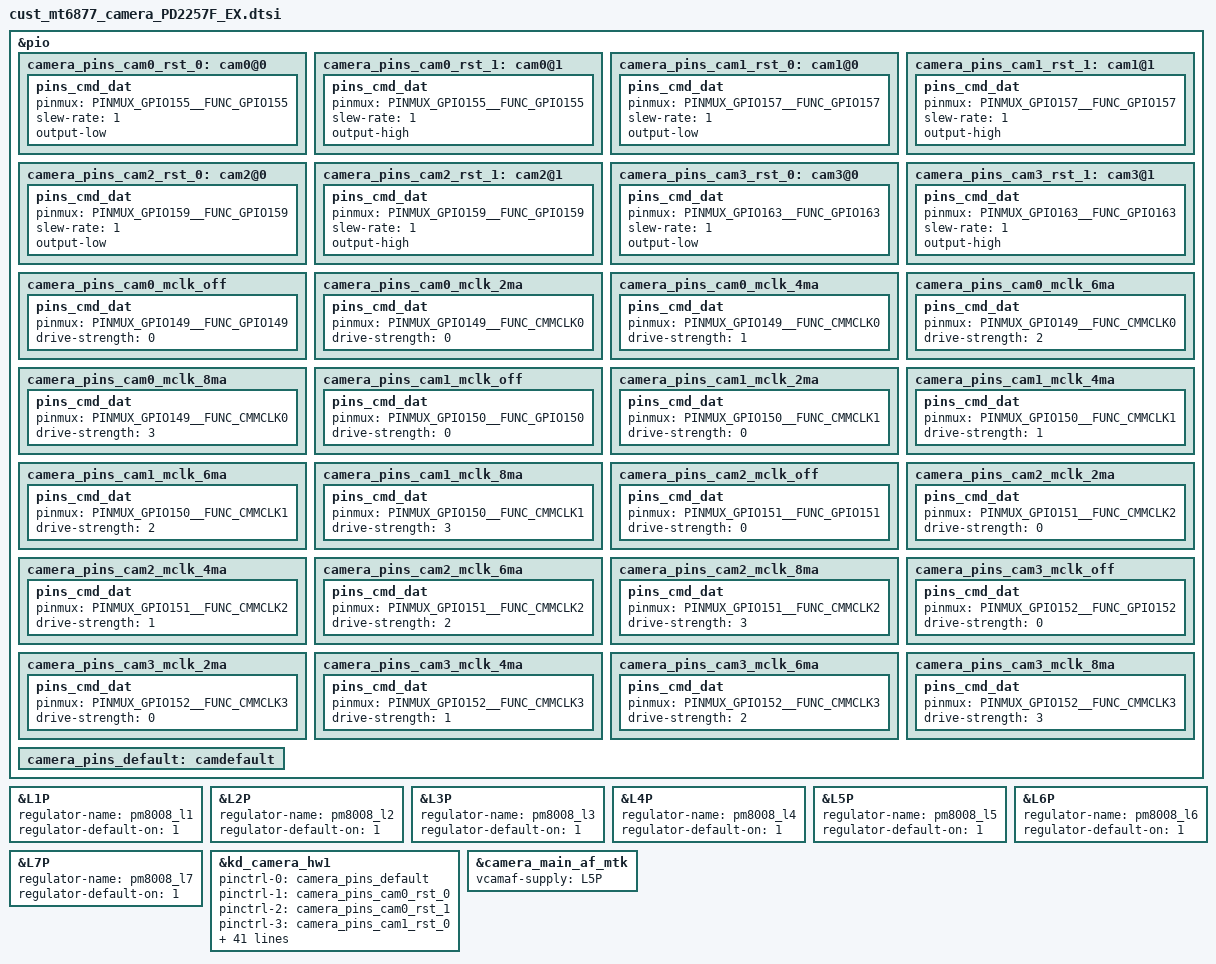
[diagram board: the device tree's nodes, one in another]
// SPDX-License-Identifier: GPL-2.0
/*
 * Copyright (c) 2021 MediaTek Inc.
 */

/* CAMERA GPIO standardization */
&pio {
	camera_pins_cam0_rst_0: cam0@0 {
		pins_cmd_dat {
			pinmux = <PINMUX_GPIO155__FUNC_GPIO155>;
			slew-rate = <1>;
			output-low;
		};
	};
	camera_pins_cam0_rst_1: cam0@1 {
		pins_cmd_dat {
			pinmux = <PINMUX_GPIO155__FUNC_GPIO155>;
			slew-rate = <1>;
			output-high;
		};
	};

	camera_pins_cam1_rst_0: cam1@0 {
		pins_cmd_dat {
			pinmux = <PINMUX_GPIO157__FUNC_GPIO157>;
			slew-rate = <1>;
			output-low;
		};
	};
	camera_pins_cam1_rst_1: cam1@1 {
		pins_cmd_dat {
			pinmux = <PINMUX_GPIO157__FUNC_GPIO157>;
			slew-rate = <1>;
			output-high;
		};
	};

	camera_pins_cam2_rst_0: cam2@0 {
		pins_cmd_dat {
			pinmux = <PINMUX_GPIO159__FUNC_GPIO159>;
			slew-rate = <1>;
			output-low;
		};
	};
	camera_pins_cam2_rst_1: cam2@1 {
		pins_cmd_dat {
			pinmux = <PINMUX_GPIO159__FUNC_GPIO159>;
			slew-rate = <1>;
			output-high;
		};
	};

	camera_pins_cam3_rst_0: cam3@0 {
		pins_cmd_dat {
			pinmux = <PINMUX_GPIO163__FUNC_GPIO163>;
			slew-rate = <1>;
			output-low;
		};
	};
	camera_pins_cam3_rst_1: cam3@1 {
		pins_cmd_dat {
			pinmux = <PINMUX_GPIO163__FUNC_GPIO163>;
			slew-rate = <1>;
			output-high;
		};
	};

	/*add for camera mclk*/
	camera_pins_cam0_mclk_off: camera_pins_cam0_mclk_off {
		pins_cmd_dat {
			pinmux = <PINMUX_GPIO149__FUNC_GPIO149>;
			drive-strength = <0>;
		};
	};
	camera_pins_cam0_mclk_2ma: camera_pins_cam0_mclk_2ma {
		pins_cmd_dat {
			pinmux = <PINMUX_GPIO149__FUNC_CMMCLK0>;
			drive-strength = <0>;
		};
	};
	camera_pins_cam0_mclk_4ma: camera_pins_cam0_mclk_4ma {
		pins_cmd_dat {
			pinmux = <PINMUX_GPIO149__FUNC_CMMCLK0>;
			drive-strength = <1>;
		};
	};
	camera_pins_cam0_mclk_6ma: camera_pins_cam0_mclk_6ma {
		pins_cmd_dat {
			pinmux = <PINMUX_GPIO149__FUNC_CMMCLK0>;
			drive-strength = <2>;
		};
	};
	camera_pins_cam0_mclk_8ma: camera_pins_cam0_mclk_8ma {
		pins_cmd_dat {
			pinmux = <PINMUX_GPIO149__FUNC_CMMCLK0>;
			drive-strength = <3>;
		};
	};
	camera_pins_cam1_mclk_off: camera_pins_cam1_mclk_off {
		pins_cmd_dat {
			pinmux = <PINMUX_GPIO150__FUNC_GPIO150>;
			drive-strength = <0>;
		};
	};
	camera_pins_cam1_mclk_2ma: camera_pins_cam1_mclk_2ma {
		pins_cmd_dat {
			pinmux = <PINMUX_GPIO150__FUNC_CMMCLK1>;
			drive-strength = <0>;
		};
	};
	camera_pins_cam1_mclk_4ma: camera_pins_cam1_mclk_4ma {
		pins_cmd_dat {
			pinmux = <PINMUX_GPIO150__FUNC_CMMCLK1>;
			drive-strength = <1>;
		};
	};
	camera_pins_cam1_mclk_6ma: camera_pins_cam1_mclk_6ma {
		pins_cmd_dat {
			pinmux = <PINMUX_GPIO150__FUNC_CMMCLK1>;
			drive-strength = <2>;
		};
	};
	camera_pins_cam1_mclk_8ma: camera_pins_cam1_mclk_8ma {
		pins_cmd_dat {
			pinmux = <PINMUX_GPIO150__FUNC_CMMCLK1>;
			drive-strength = <3>;
		};
	};
	camera_pins_cam2_mclk_off: camera_pins_cam2_mclk_off {
		pins_cmd_dat {
			pinmux = <PINMUX_GPIO151__FUNC_GPIO151>;
			drive-strength = <0>;
		};
	};
	camera_pins_cam2_mclk_2ma: camera_pins_cam2_mclk_2ma {
		pins_cmd_dat {
			pinmux = <PINMUX_GPIO151__FUNC_CMMCLK2>;
			drive-strength = <0>;
		};
	};
	camera_pins_cam2_mclk_4ma: camera_pins_cam2_mclk_4ma {
		pins_cmd_dat {
			pinmux = <PINMUX_GPIO151__FUNC_CMMCLK2>;
			drive-strength = <1>;
		};
	};
	camera_pins_cam2_mclk_6ma: camera_pins_cam2_mclk_6ma {
		pins_cmd_dat {
			pinmux = <PINMUX_GPIO151__FUNC_CMMCLK2>;
			drive-strength = <2>;
		};
	};
	camera_pins_cam2_mclk_8ma: camera_pins_cam2_mclk_8ma {
		pins_cmd_dat {
			pinmux = <PINMUX_GPIO151__FUNC_CMMCLK2>;
			drive-strength = <3>;
		};
	};
	camera_pins_cam3_mclk_off: camera_pins_cam3_mclk_off {
		pins_cmd_dat {
			pinmux = <PINMUX_GPIO152__FUNC_GPIO152>;
			drive-strength = <0>;
		};
	};
	camera_pins_cam3_mclk_2ma: camera_pins_cam3_mclk_2ma {
		pins_cmd_dat {
			pinmux = <PINMUX_GPIO152__FUNC_CMMCLK3>;
			drive-strength = <0>;
		};
	};
	camera_pins_cam3_mclk_4ma: camera_pins_cam3_mclk_4ma {
		pins_cmd_dat {
			pinmux = <PINMUX_GPIO152__FUNC_CMMCLK3>;
			drive-strength = <1>;
		};
	};
	camera_pins_cam3_mclk_6ma: camera_pins_cam3_mclk_6ma {
		pins_cmd_dat {
			pinmux = <PINMUX_GPIO152__FUNC_CMMCLK3>;
			drive-strength = <2>;
		};
	};
	camera_pins_cam3_mclk_8ma: camera_pins_cam3_mclk_8ma {
		pins_cmd_dat {
			pinmux = <PINMUX_GPIO152__FUNC_CMMCLK3>;
			drive-strength = <3>;
		};
	};
	camera_pins_default: camdefault {
	};
};

/* hope add pm8008 pmic start*/
&L1P {
	regulator-name = "pm8008_l1";
	regulator-default-on = <1>; /* 0:skip, 1: off, 2:on */
	status = "okay";
};

&L2P {
	regulator-name = "pm8008_l2";
	regulator-default-on = <1>; /* 0:skip, 1: off, 2:on */
	status = "okay";
};

&L3P {
	regulator-name = "pm8008_l3";
	regulator-default-on = <1>; /* 0:skip, 1: off, 2:on */
	status = "okay";
};

&L4P {
	regulator-name = "pm8008_l4";
	regulator-default-on = <1>; /* 0:skip, 1: off, 2:on */
	status = "okay";
};

&L5P {
	regulator-name = "pm8008_l5";
	regulator-default-on = <1>; /* 0:skip, 1: off, 2:on */
	status = "okay";
};

&L6P {
	regulator-name = "pm8008_l6";
	regulator-default-on = <1>; /* 0:skip, 1: off, 2:on */
	status = "okay";
};

&L7P {
	regulator-name = "pm8008_l7";
	regulator-default-on = <1>; /* 0:skip, 1: off, 2:on */
	status = "okay";
};

/* hope add pm8008 pmic end*/
&kd_camera_hw1 {
	pinctrl-names = "default",
			"cam0_rst0", "cam0_rst1",
			"cam1_rst0", "cam1_rst1",
			"cam2_rst0", "cam2_rst1",
			"cam3_rst0", "cam3_rst1",
			"cam0_mclk_off",
			"cam0_mclk_2mA", "cam0_mclk_4mA",
			"cam0_mclk_6mA", "cam0_mclk_8mA",
			"cam1_mclk_off",
			"cam1_mclk_2mA", "cam1_mclk_4mA",
			"cam1_mclk_6mA", "cam1_mclk_8mA",
			"cam2_mclk_off",
			"cam2_mclk_2mA", "cam2_mclk_4mA",
			"cam2_mclk_6mA", "cam2_mclk_8mA",
			"cam3_mclk_off",
			"cam3_mclk_2mA", "cam3_mclk_4mA",
			"cam3_mclk_6mA", "cam3_mclk_8mA";
	pinctrl-0 = <&camera_pins_default>;
	pinctrl-1 = <&camera_pins_cam0_rst_0>;
	pinctrl-2 = <&camera_pins_cam0_rst_1>;
	pinctrl-3 = <&camera_pins_cam1_rst_0>;
	pinctrl-4 = <&camera_pins_cam1_rst_1>;
	pinctrl-5 = <&camera_pins_cam2_rst_0>;
	pinctrl-6 = <&camera_pins_cam2_rst_1>;
	pinctrl-7 = <&camera_pins_cam3_rst_0>;
	pinctrl-8 = <&camera_pins_cam3_rst_1>;
	pinctrl-9 = <&camera_pins_cam0_mclk_off>;
	pinctrl-10 = <&camera_pins_cam0_mclk_2ma>;
	pinctrl-11 = <&camera_pins_cam0_mclk_4ma>;
	pinctrl-12 = <&camera_pins_cam0_mclk_6ma>;
	pinctrl-13 = <&camera_pins_cam0_mclk_8ma>;
	pinctrl-14 = <&camera_pins_cam1_mclk_off>;
	pinctrl-15 = <&camera_pins_cam1_mclk_2ma>;
	pinctrl-16 = <&camera_pins_cam1_mclk_4ma>;
	pinctrl-17 = <&camera_pins_cam1_mclk_6ma>;
	pinctrl-18 = <&camera_pins_cam1_mclk_8ma>;
	pinctrl-19 = <&camera_pins_cam2_mclk_off>;
	pinctrl-20 = <&camera_pins_cam2_mclk_2ma>;
	pinctrl-21 = <&camera_pins_cam2_mclk_4ma>;
	pinctrl-22 = <&camera_pins_cam2_mclk_6ma>;
	pinctrl-23 = <&camera_pins_cam2_mclk_8ma>;
	pinctrl-24 = <&camera_pins_cam3_mclk_off>;
	pinctrl-25 = <&camera_pins_cam3_mclk_2ma>;
	pinctrl-26 = <&camera_pins_cam3_mclk_4ma>;
	pinctrl-27 = <&camera_pins_cam3_mclk_6ma>;
	pinctrl-28 = <&camera_pins_cam3_mclk_8ma>;

	cam0_vcamio-supply = <&L6P>;/*dovdd*/
	cam1_vcamio-supply = <&L6P>;
	cam2_vcamio-supply = <&L6P>;
	cam3_vcamio-supply = <&L6P>;

	cam0_vcama-supply = <&L4P>;/*avdd*/
	cam1_vcama-supply = <&L3P>;
	cam2_vcama-supply = <&L3P>;
	cam3_vcama-supply = <&L3P>;

	cam0_vcamd-supply = <&L2P>;/*dvdd*/
	cam1_vcamd-supply = <&L1P>;

	cam0_vcamoisa-supply = <&L7P>;/*oisavdd*/

	cam0_enable_sensor = "s5kgw3sp13pd2257f_mipi_raw";
	cam1_enable_sensor = "s5k3p9sp04pd2257f_mipi_raw";
	cam2_enable_sensor = "gc02m1pd2257f_mipi_raw gc02m1bzpd2257f_mipi_mono";
	cam3_enable_sensor = "gc02m1bpd2257f_mipi_mono";
	status = "okay";
};
/* CAMERA GPIO end */

/* CAMERA AF */
&camera_main_af_mtk {
vcamaf-supply = <&L5P>;/*afvdd*/
	status = "okay";
};
/* CAMERA AF end */
